# STM32H5E5xx register map
File version: 1.0
Registers are 32-bit, read-write, reset 0x0 unless marked. A register's access mark holds for its fields unless they carry their own. Offsets are from the block's base; [hi:lo] are bit positions; lines under a group give offsets from that group; {n}, {i} and the like mark numbered series; 'fields as' and 'values as' point back to an identical list.

## FLASH — FLASH Registers
Base 0x40022000
Same registers: FLASH_S 0x50022000
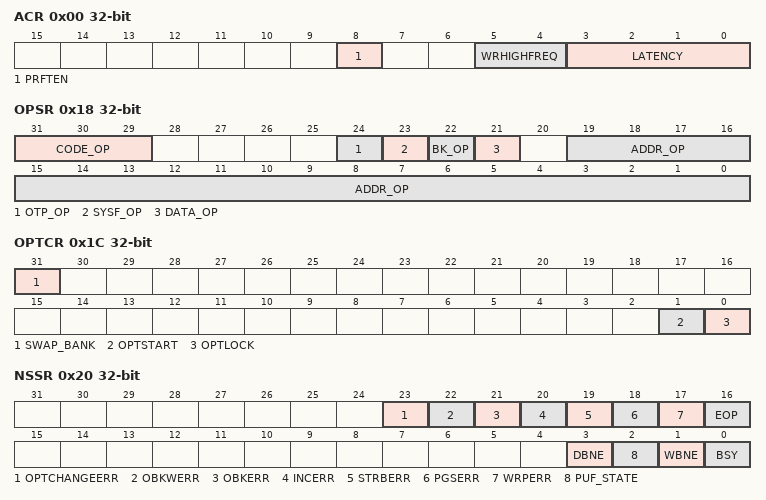
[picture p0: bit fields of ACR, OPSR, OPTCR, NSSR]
0x00 ACR — FLASH access control register
  [8] PRFTEN — Prefetch enable
  [5:4] WRHIGHFREQ — Flash signal delay
  [3:0] LATENCY
    0=FLASH zero wait state; 1=FLASH one wait state; 2=FLASH two wait states; 3=FLASH three wait states; 4=FLASH four wait states; 5=FLASH five wait states; 6=FLASH six wait state; 7=FLASH Seven wait states; 8=FLASH Eight wait states; 9=FLASH nine wait states; 10=FLASH ten wait states; 11=FLASH eleven wait states; 12=FLASH twelve wait states; 13=FLASH thirteen wait states; 14=FLASH fourteen wait states; 15=FLASH fifteen wait states
0x04 NSKEYR — FLASH non-secure key register
0x08 SECKEYR — FLASH secure key register
0x0C OPTKEYR — FLASH option key register
0x10 NSOBKKEYR — FLASH non-secure option bytes keys key register
0x14 SECOBKKEYR — FLASH secure option bytes keys key register
0x18 OPSR — FLASH OPSR register
  [31:29] CODE_OP — Flash memory operation code
  [24] OTP_OP — Operation in OTP area interrupted
  [23] SYSF_OP — Operation in System Flash interrupted
  [22] BK_OP — Interrupted operation bank
  [21] DATA_OP — Operation in Flash high-cycle data area interrupted
  [19:0] ADDR_OP — Interrupted operation address
0x1C OPTCR — Flash Option Control Register
  [31] SWAP_BANK — Bank swapping option configuration bit
  [1] OPTSTART — Option byte start change option configuration bit
  [0] OPTLOCK — FLASH_OPTCR lock option configuration bit
0x20 NSSR — FLASH non-secure status register
  [23] OPTCHANGEERR — Option byte change error flag
  [22] OBKWERR — OBK write error flag
  [21] OBKERR — OBK general error flag
  [20] INCERR — Inconsistency error flag
  [19] STRBERR — Strobe error flag
  [18] PGSERR — Programming sequence error flag
  [17] WRPERR — Write protection error flag
  [16] EOP — End-of-program flag
  [3] DBNE — Data buffer not empty flag
  [2] PUF_STATE — PUF STATE flag
  [1] WBNE — Write buffer not empty flag
  [0] BSY — Busy flag
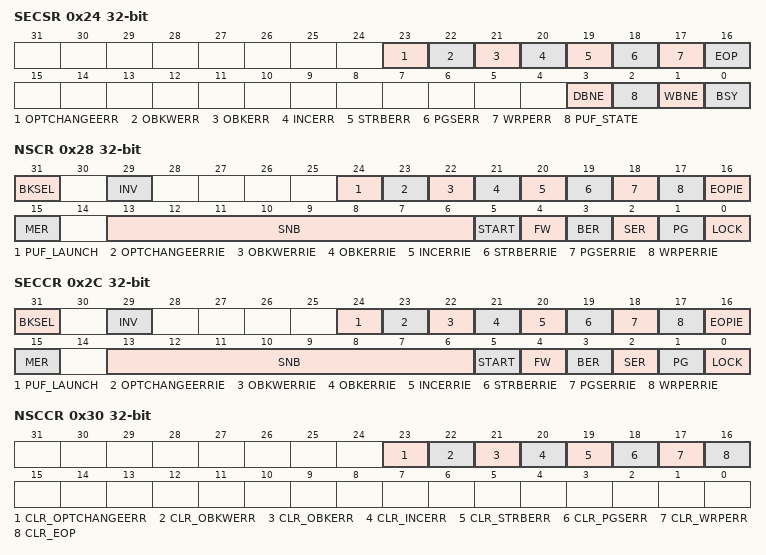
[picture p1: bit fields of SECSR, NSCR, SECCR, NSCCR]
0x24 SECSR — FLASH secure status register
  fields as NSSR
0x28 NSCR — FLASH non-secure control register
  [31] BKSEL — Bank selector
  [29] INV — Flash Security State Invert
  [24] PUF_LAUNCH — PUF preparation start control bit
  [23] OPTCHANGEERRIE — Option byte change error interrupt enable bit
  [22] OBKWERRIE — OBK write error interrupt enable bit
  [21] OBKERRIE — OBK general error interrupt enable bitt
  [20] INCERRIE — Inconsistency error interrupt enable bit
  [19] STRBERRIE — Strobe error interrupt enable bit
  [18] PGSERRIE — Programming sequence error interrupt enable bit
  [17] WRPERRIE — Write protection error interrupt enable bit
  [16] EOPIE — End-of-operation interrupt control bit
  [15] MER — Mass erase
  [13:6] SNB — Sector erase selection number
  [5] START — Erase start control bit
  [4] FW — Write forcing control bit
  [3] BER — Bank erase request
  [2] SER — Sector erase request
  [1] PG — Programming control bit
  [0] LOCK — Configuration lock bit
0x2C SECCR — FLASH secure control register
  fields as NSCR
0x30 NSCCR — FLASH non-secure clear control register
  [23] CLR_OPTCHANGEERR — Option byte change error clear bit
  [22] CLR_OBKWERR — OBKWERR flag clear bit
  [21] CLR_OBKERR — OBKERR flag clear bit
  [20] CLR_INCERR — INCERR flag clear bit
  [19] CLR_STRBERR — STRBERR flag clear bit
  [18] CLR_PGSERR — PGSERR flag clear bit
  [17] CLR_WRPERR — WRPERR flag clear bit
  [16] CLR_EOP — EOP flag clear bit
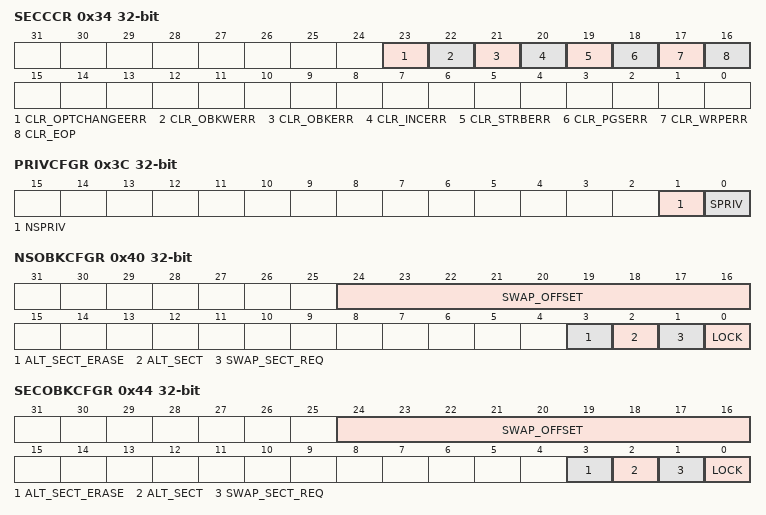
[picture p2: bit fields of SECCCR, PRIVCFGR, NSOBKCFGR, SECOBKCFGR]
0x34 SECCCR — FLASH secure clear control register
  fields as NSCCR
0x3C PRIVCFGR — FLASH privilege configuration register
  [1] NSPRIV — Privilege protection for non-secure registers
  [0] SPRIV — Privilege protection for secure registers
0x40 NSOBKCFGR — FLASH non-secure option byte key configuration register
  [24:16] SWAP_OFFSET
  [3] ALT_SECT_ERASE — Alternate sector erase
  [2] ALT_SECT — Alternate sector
  [1] SWAP_SECT_REQ — OBK swap sector request
  [0] LOCK — OBKCFGR lock
0x44 SECOBKCFGR — FLASH secure option byte key configuration register
  fields as NSOBKCFGR
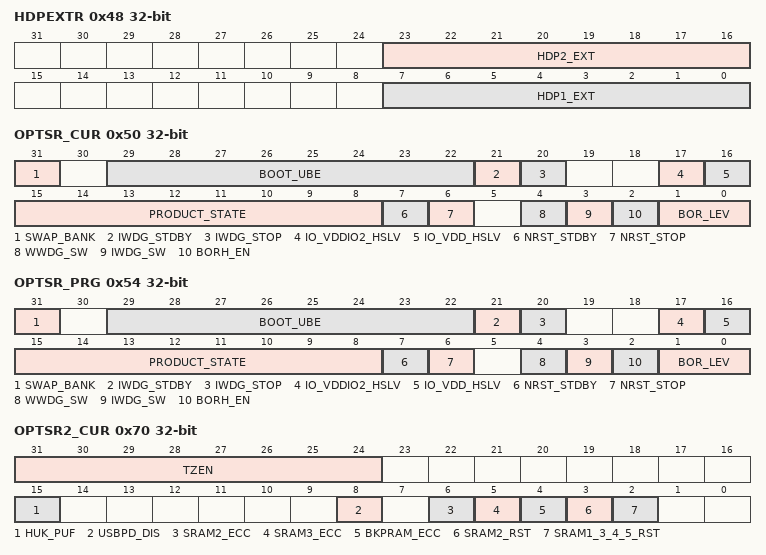
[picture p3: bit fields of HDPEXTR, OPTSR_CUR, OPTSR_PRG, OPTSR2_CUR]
0x48 HDPEXTR — FLASH HDP extension register
  [23:16] HDP2_EXT — HDP area extension in 8kB sectors in bank 2
  [7:0] HDP1_EXT — HDP area extension in 8kB sectors in bank 1
0x50 OPTSR_CUR — FLASH option status current register
  [31] SWAP_BANK — Bank swapping option bit
  [29:22] BOOT_UBE — Unique boot entry option byte
  [21] IWDG_STDBY — Independent watchdog counter freeze in Standby mode
  [20] IWDG_STOP — Independent watchdog counter freeze in Stop mode
  [17] IO_VDDIO2_HSLV — VDDIO2 I/O high-speed at low-voltage option bit
  [16] IO_VDD_HSLV — VDD I/O high-speed at low-voltage option bit
  [15:8] PRODUCT_STATE — Life state code option byte
  [7] NRST_STDBY — Standby mode entry reset option bit
  [6] NRST_STOP — Stop mode entry reset option bit
  [4] WWDG_SW — WWDG control mode option bit
  [3] IWDG_SW — IWDG control mode option bit
  [2] BORH_EN — Brownout high enable configuration bit
  [1:0] BOR_LEV — Brownout level option bit
0x54 OPTSR_PRG — FLASH option status to program register
  fields as OPTSR_CUR
0x60 NSEPOCHR_CUR — FLASH non-secure epoch current register
0x64 NSEPOCHR_PRG — FLASH non-secure epoch to program register
0x68 SECEPOCHR_CUR — FLASH secure epoch current register
0x6C SECEPOCHR_PRG — FLASH secure epoch to program register
0x70 OPTSR2_CUR — FLASH option status current register 2
  [31:24] TZEN — TrustZone enable
  [15] HUK_PUF — HUK source is PUF
  [8] USBPD_DIS — USB power delivery configuration disable
  [6] SRAM2_ECC — SRAM2 ECC detection and correction disable
  [5] SRAM3_ECC — SRAM3 ECC detection and correction enable
  [4] BKPRAM_ECC — Backup RAM ECC detection and correction enable
  [3] SRAM2_RST — SRAM2 erased when a system reset occurs
  [2] SRAM1_3_4_5_RST — SRAM1, SRAM3, SRAM4 and SRAM5 erased when a system reset occurs
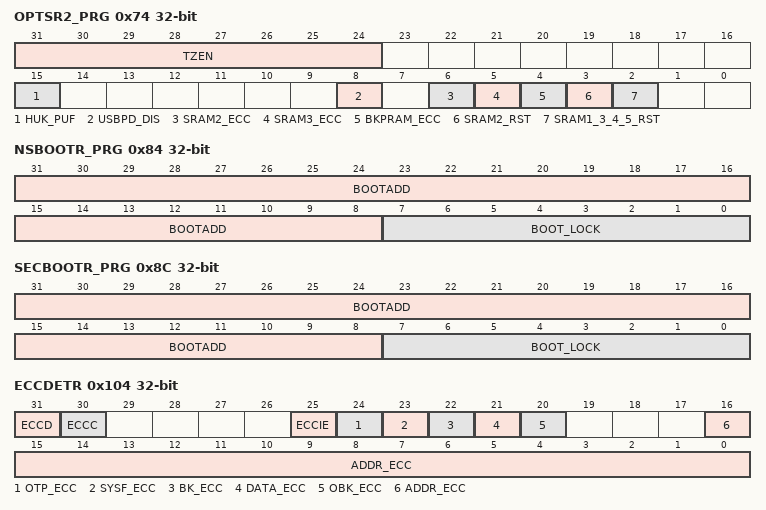
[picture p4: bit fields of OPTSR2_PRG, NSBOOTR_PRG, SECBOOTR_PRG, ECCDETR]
0x74 OPTSR2_PRG — FLASH option status to program register 2
  fields as OPTSR2_CUR
0x80 NSBOOTR_CUR — FLASH non-secure unique boot entry current register
0x84 NSBOOTR_PRG — FLASH non-secure unique boot entry to program register
  [31:8] BOOTADD — Boot address
  [7:0] BOOT_LOCK
0x88 SECBOOTR_CUR — FLASH secure unique boot entry current register
0x8C SECBOOTR_PRG — FLASH secure unique boot entry to program register
  [31:8] BOOTADD — Boot address
  [7:0] BOOT_LOCK
0x90 OTPBLR_CUR — FLASH OTP block lock current register
0x94 OTPBLR_PRG — FLASH OTP block Lock to program register
0x98 WRP12R_CUR — FLASH write sector group 1 protection for Bank2 current register
0x9C WRP12R_PRG — FLASH write sector group 1 protection for Bank2 to program register
{0x9C+4i} SECBB1R{i} (i=1..8) — FLASH secure block-based bank 1 register {i}
{0xBC+4i} PRIVBB1R{i} (i=1..8) — FLASH privilege block-based bank 1 register {i}
0xE0 SECWM1R_CUR — FLASH secure watermark 1 current register
0xE4 SECWM1R_PRG — FLASH secure watermark 1 to program register
0xE8 WRP11R_CUR — FLASH write sector group protection current register for bank1
0xEC WRP11R_PRG — FLASH write sector group protection to program register for bank1
0xF0 EDATA1R_CUR — FLASH data sectors configuration current register for bank1
0xF4 EDATA1R_PRG — FLASH data sectors configuration to program register for bank1
0xF8 HDP1R_CUR — FLASH HDP configuration current register for bank1
0xFC HDP1R_PRG — FLASH HDP configuration to program register for bank1
0x100 ECCCORR — FLASH ECC correction register
0x104 ECCDETR — FLASH ECC detection register
  [31] ECCD — ECC detection
  [30] ECCC — ECC correction
  [25] ECCIE — ECC correction interrupt enable
  [24] OTP_ECC — Flash OTP ECC fail
  [23] SYSF_ECC — System Flash ECC fail
  [22] BK_ECC — ECC fail bank
  [21] DATA_ECC — Flash high-cycle data ECC fail
  [20] OBK_ECC — Flash OB Keys storage area ECC fail
  [16:0] ADDR_ECC — ECC fail address
0x108 ECCDR — FLASH ECC data register
  [15:0] FAIL_DATA — ECC fail data
0x198 WRP22R_CUR — FLASH write sector group 2 protection for Bank2 current register
0x19C WRP22R_PRG — FLASH write sector group 2 protection for Bank2 to program register
{0x19C+4i} SECBB2R{i} (i=1..8) — FLASH secure block-based bank 2 register {i}
{0x1BC+4i} PRIVBB2R{i} (i=1..8) — FLASH privilege block-based bank 2 register {i}
0x1E0 SECWM2R_CUR — FLASH secure watermark 2 current register
0x1E4 SECWM2R_PRG — FLASH secure watermark 2 to program register
0x1E8 WRP21R_CUR — FLASH write sector group protection current register for bank2
0x1EC WRP21R_PRG — FLASH write sector group protection to program register for bank2
0x1F0 EDATA2R_CUR — FLASH data sectors configuration current register for bank2
0x1F4 EDATA2R_PRG — FLASH data sectors configuration to program register for bank2
0x1F8 HDP2R_CUR — FLASH HDP configuration current register for bank2
0x1FC HDP2R_PRG — FLASH HDP configuration to program register for bank2
